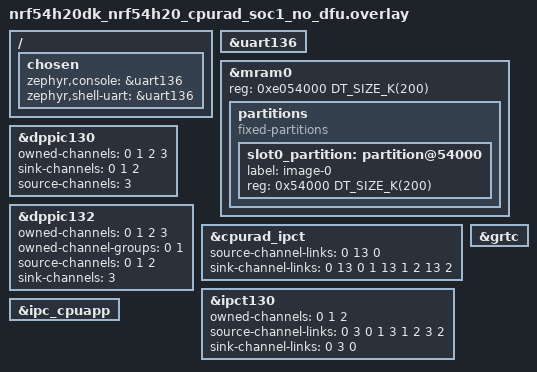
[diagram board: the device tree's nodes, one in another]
/*
 * Copyright (c) 2023 Nordic Semiconductor ASA
 *
 * SPDX-License-Identifier: Apache-2.0
 */

 /delete-node/ &slot0_partition;
 
 / {
    chosen {
        zephyr,console = &uart136;
        zephyr,shell-uart = &uart136;
    };
 };

 &uart136 {
    status = "okay";
};

&mram0 {
    reg = <0xe054000 DT_SIZE_K(200)>;
    partitions {
        compatible = "fixed-partitions";
        slot0_partition: partition@54000 {
            label = "image-0";
            reg = < 0x54000 DT_SIZE_K(200) >;
        };
    };
};

&dppic130 {
	owned-channels = <0 1 2 3>;
	sink-channels = <0 1 2>;
	source-channels = <3>;
	status = "okay";
};

&dppic132 {
	owned-channels = <0 1 2 3>;
	owned-channel-groups = <0 1>;
	source-channels = <0 1 2>;
	sink-channels = <3>;
	status = "okay";
};

&cpurad_ipct {
	source-channel-links = <0 13 0>;
	sink-channel-links = <0 13 0
			      1 13 1
			      2 13 2>;
};

&ipct130 {
	status = "okay";
	owned-channels = <0 1 2>;
	source-channel-links = <0 3 0
				1 3 1
				2 3 2>;
	sink-channel-links = <0 3 0>;
};

&grtc {
	status = "okay";
};

ipc0: &ipc_cpuapp { };
